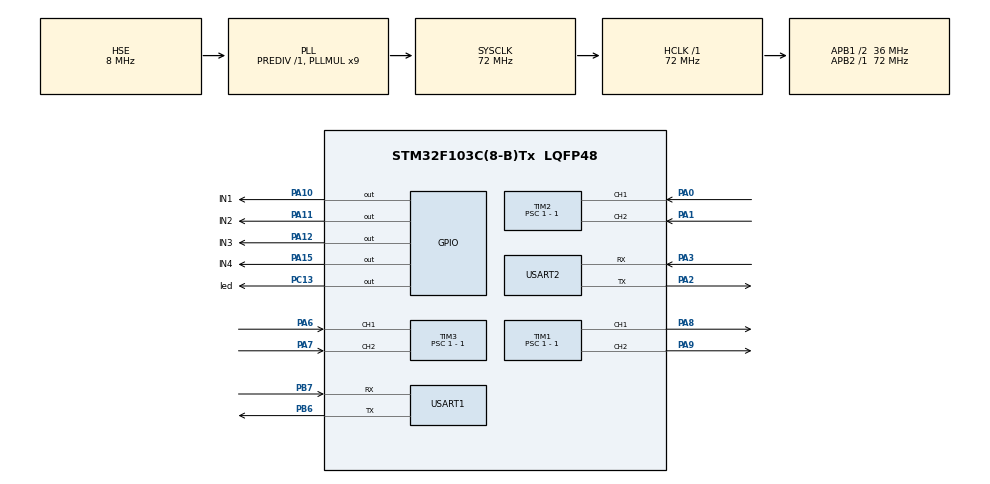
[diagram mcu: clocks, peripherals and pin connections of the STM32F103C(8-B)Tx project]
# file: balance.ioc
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Dma.Request0=USART1_RX
Dma.Request1=USART2_RX
Dma.USART1_RX.0.Direction=DMA_PERIPH_TO_MEMORY
Dma.USART1_RX.0.Instance=DMA1_Channel5
Dma.USART1_RX.0.MemDataAlignment=DMA_MDATAALIGN_BYTE
Dma.USART1_RX.0.MemInc=DMA_MINC_ENABLE
Dma.USART1_RX.0.Mode=DMA_NORMAL
Dma.USART1_RX.0.PeriphDataAlignment=DMA_PDATAALIGN_BYTE
Dma.USART1_RX.0.PeriphInc=DMA_PINC_DISABLE
Dma.USART1_RX.0.Priority=DMA_PRIORITY_VERY_HIGH
Dma.USART2_RX.1.Direction=DMA_PERIPH_TO_MEMORY
Dma.USART2_RX.1.Instance=DMA1_Channel6
Dma.USART2_RX.1.MemDataAlignment=DMA_MDATAALIGN_BYTE
Dma.USART2_RX.1.MemInc=DMA_MINC_ENABLE
Dma.USART2_RX.1.Mode=DMA_NORMAL
Dma.USART2_RX.1.PeriphDataAlignment=DMA_PDATAALIGN_BYTE
Dma.USART2_RX.1.PeriphInc=DMA_PINC_DISABLE
Dma.USART2_RX.1.Priority=DMA_PRIORITY_HIGH
Mcu.Family=STM32F1
Mcu.Name=STM32F103C(8-B)Tx
Mcu.Package=LQFP48
NVIC.DMA1_Channel5_IRQn=true\:0\:0\:false\:false\:true\:false\:true
NVIC.DMA1_Channel6_IRQn=true\:0\:0\:false\:false\:true\:false\:true
NVIC.PriorityGroup=NVIC_PRIORITYGROUP_4
NVIC.TIM4_IRQn=true\:0\:0\:false\:false\:true\:true\:true
NVIC.USART1_IRQn=true\:1\:0\:true\:false\:true\:true\:true
NVIC.USART2_IRQn=true\:2\:0\:true\:false\:true\:true\:true
PA0-WKUP.Signal=S_TIM2_CH1_ETR
PA1.Signal=S_TIM2_CH2
PA10.GPIO_Label=IN1
PA10.Signal=GPIO_Output
PA11.GPIO_Label=IN2
PA11.Signal=GPIO_Output
PA12.GPIO_Label=IN3
PA12.Signal=GPIO_Output
PA13.Mode=Serial_Wire
PA13.Signal=SYS_JTMS-SWDIO
PA14.Mode=Serial_Wire
PA14.Signal=SYS_JTCK-SWCLK
PA15.GPIO_Label=IN4
PA15.Signal=GPIO_Output
PA2.Mode=Asynchronous
PA2.Signal=USART2_TX
PA3.Mode=Asynchronous
PA3.Signal=USART2_RX
PA6.Signal=S_TIM3_CH1
PA7.Signal=S_TIM3_CH2
PA8.Signal=S_TIM1_CH1
PA9.Signal=S_TIM1_CH2
PB6.Mode=Asynchronous
PB6.Signal=USART1_TX
PB7.Mode=Asynchronous
PB7.Signal=USART1_RX
PC13-TAMPER-RTC.GPIO_Label=led
PC13-TAMPER-RTC.Signal=GPIO_Output
PD0-OSC_IN.Mode=HSE-External-Oscillator
PD0-OSC_IN.Signal=RCC_OSC_IN
PD1-OSC_OUT.Mode=HSE-External-Oscillator
PD1-OSC_OUT.Signal=RCC_OSC_OUT
ProjectManager.HeapSize=0x200
ProjectManager.StackSize=0x400
ProjectManager.TargetToolchain=MDK-ARM V5.27
RCC.AHBFreq_Value=72000000
RCC.APB1CLKDivider=RCC_HCLK_DIV2
RCC.APB1Freq_Value=36000000
RCC.APB1TimFreq_Value=72000000
RCC.APB2Freq_Value=72000000
RCC.APB2TimFreq_Value=72000000
RCC.EnbaleCSS=true
RCC.HCLKFreq_Value=72000000
RCC.PLLMUL=RCC_PLL_MUL9
RCC.PLLSourceVirtual=RCC_PLLSOURCE_HSE
RCC.SYSCLKFreq_VALUE=72000000
RCC.SYSCLKSource=RCC_SYSCLKSOURCE_PLLCLK
RCC.USBFreq_Value=72000000
SH.S_TIM1_CH1.0=TIM1_CH1,PWM Generation1 CH1
SH.S_TIM1_CH2.0=TIM1_CH2,PWM Generation2 CH2
SH.S_TIM2_CH1_ETR.0=TIM2_CH1,Encoder_Interface
SH.S_TIM2_CH2.0=TIM2_CH2,Encoder_Interface
SH.S_TIM3_CH1.0=TIM3_CH1,Encoder_Interface
SH.S_TIM3_CH2.0=TIM3_CH2,Encoder_Interface
TIM1.Channel-PWM\ Generation1\ CH1=TIM_CHANNEL_1
TIM1.Channel-PWM\ Generation2\ CH2=TIM_CHANNEL_2
TIM1.Period=7200 - 1
TIM1.Prescaler=1 - 1
TIM2.Prescaler=1 - 1
TIM3.Prescaler=1 - 1
TIM4.Period=10000 - 1
TIM4.Prescaler=72 - 1
USART1.VirtualMode=VM_ASYNC
USART2.VirtualMode=VM_ASYNC
VP_TIM1_VS_ClockSourceINT.Mode=Internal
VP_TIM4_VS_ClockSourceINT.Mode=Internal
board=custom

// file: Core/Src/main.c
/* USER CODE BEGIN Header */
/**
  ******************************************************************************
  * @file           : main.c
  * @brief          : Main program body
  ******************************************************************************
  * @attention
  *
  * <h2><center>&copy; Copyright (c) 2021 STMicroelectronics.
  * All rights reserved.</center></h2>
  *
  * This software component is licensed by ST under BSD 3-Clause license,
  * the "License"; You may not use this file except in compliance with the
  * License. You may obtain a copy of the License at:
  *                        opensource.org/licenses/BSD-3-Clause
  *
  ******************************************************************************
  */
/* USER CODE END Header */
#include "main.h"
#include "dma.h"
#include "tim.h"
#include "usart.h"
#include "gpio.h"

/* USER CODE BEGIN Includes */
#include "gyro_driver.h"
#include "encoder.h"
/* USER CODE END Includes */

/* USER CODE BEGIN PV */
//����������ָ��
//volatile static gyro_driver_handle_t * pgyro = NULL;
//����������ָ��
//volatile static ecd_t * pecd = NULL;
/* USER CODE END PV */

void SystemClock_Config(void);
/* USER CODE BEGIN PFP */
static void bsp_init(void);
/* USER CODE END PFP */

int main(void)
{

  /* MCU Configuration--------------------------------------------------------*/

  /* Reset of all peripherals, Initializes the Flash interface and the Systick. */
  HAL_Init();

  /* Configure the system clock */
  SystemClock_Config();

  /* Initialize all configured peripherals */
  MX_GPIO_Init();
  MX_DMA_Init();
  MX_TIM1_Init();
  MX_USART1_UART_Init();
  MX_TIM2_Init();
  MX_TIM3_Init();
  MX_TIM4_Init();
  MX_USART2_UART_Init();
  /* USER CODE BEGIN 2 */
	bsp_init();
  /* USER CODE END 2 */

  /* Infinite loop */
  /* USER CODE BEGIN WHILE */
  while (1)
  {
	  HAL_Delay(20);
    /* USER CODE END WHILE */

  }
}

void SystemClock_Config(void)
{
  RCC_OscInitTypeDef RCC_OscInitStruct = {0};
  RCC_ClkInitTypeDef RCC_ClkInitStruct = {0};

  /** Initializes the RCC Oscillators according to the specified parameters
  * in the RCC_OscInitTypeDef structure.
  */
  RCC_OscInitStruct.OscillatorType = RCC_OSCILLATORTYPE_HSE;
  RCC_OscInitStruct.HSEState = RCC_HSE_ON;
  RCC_OscInitStruct.HSEPredivValue = RCC_HSE_PREDIV_DIV1;
  RCC_OscInitStruct.HSIState = RCC_HSI_ON;
  RCC_OscInitStruct.PLL.PLLState = RCC_PLL_ON;
  RCC_OscInitStruct.PLL.PLLSource = RCC_PLLSOURCE_HSE;
  RCC_OscInitStruct.PLL.PLLMUL = RCC_PLL_MUL9;
  if (HAL_RCC_OscConfig(&RCC_OscInitStruct) != HAL_OK)
  {
    Error_Handler();
  }
  /** Initializes the CPU, AHB and APB buses clocks
  */
  RCC_ClkInitStruct.ClockType = RCC_CLOCKTYPE_HCLK|RCC_CLOCKTYPE_SYSCLK
                              |RCC_CLOCKTYPE_PCLK1|RCC_CLOCKTYPE_PCLK2;
  RCC_ClkInitStruct.SYSCLKSource = RCC_SYSCLKSOURCE_PLLCLK;
  RCC_ClkInitStruct.AHBCLKDivider = RCC_SYSCLK_DIV1;
  RCC_ClkInitStruct.APB1CLKDivider = RCC_HCLK_DIV2;
  RCC_ClkInitStruct.APB2CLKDivider = RCC_HCLK_DIV1;

  if (HAL_RCC_ClockConfig(&RCC_ClkInitStruct, FLASH_LATENCY_2) != HAL_OK)
  {
    Error_Handler();
  }
  /** Enables the Clock Security System
  */
  HAL_RCC_EnableCSS();
}

/* USER CODE BEGIN 4 */
static void bsp_init(void){
	HAL_Delay(1500);
	GYRO_init();
	HAL_Delay(1500);
	ecd_init();
}
/* USER CODE END 4 */

void Error_Handler(void)
{
  __disable_irq();
  while (1)
  {
  }
}

/************************ (C) COPYRIGHT STMicroelectronics *****END OF FILE****/
